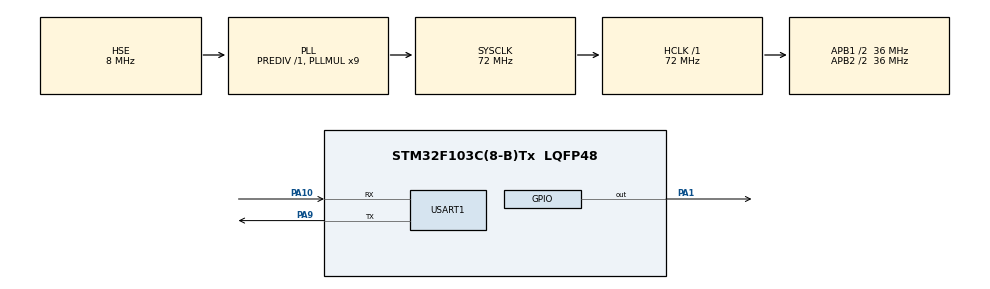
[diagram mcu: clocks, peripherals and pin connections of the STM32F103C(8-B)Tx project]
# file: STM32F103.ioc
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Mcu.Family=STM32F1
Mcu.Name=STM32F103C(8-B)Tx
Mcu.Package=LQFP48
NVIC.PriorityGroup=NVIC_PRIORITYGROUP_4
NVIC.USART1_IRQn=true\:0\:0\:false\:false\:true\:true\:true\:true
PA0-WKUP.Mode=SYS_WakeUp0
PA0-WKUP.Signal=SYS_WKUP
PA1.Signal=GPIO_Output
PA10.Mode=Asynchronous
PA10.Signal=USART1_RX
PA13.Mode=Serial_Wire
PA13.Signal=SYS_JTMS-SWDIO
PA14.Mode=Serial_Wire
PA14.Signal=SYS_JTCK-SWCLK
PA9.Mode=Asynchronous
PA9.Signal=USART1_TX
PD0-OSC_IN.Mode=HSE-External-Oscillator
PD0-OSC_IN.Signal=RCC_OSC_IN
PD1-OSC_OUT.Mode=HSE-External-Oscillator
PD1-OSC_OUT.Signal=RCC_OSC_OUT
ProjectManager.HeapSize=0x200
ProjectManager.StackSize=0x400
ProjectManager.TargetToolchain=MDK-ARM V5.32
RCC.AHBFreq_Value=72000000
RCC.APB1CLKDivider=RCC_HCLK_DIV2
RCC.APB1Freq_Value=36000000
RCC.APB1TimFreq_Value=72000000
RCC.APB2CLKDivider=RCC_HCLK_DIV2
RCC.APB2Freq_Value=36000000
RCC.APB2TimFreq_Value=72000000
RCC.HCLKFreq_Value=72000000
RCC.PLLMUL=RCC_PLL_MUL9
RCC.PLLSourceVirtual=RCC_PLLSOURCE_HSE
RCC.SYSCLKFreq_VALUE=72000000
RCC.SYSCLKSource=RCC_SYSCLKSOURCE_PLLCLK
RCC.USBFreq_Value=72000000
TIM2.Prescaler=71
USART1.VirtualMode=VM_ASYNC
VP_TIM2_VS_ClockSourceINT.Mode=Internal
board=custom

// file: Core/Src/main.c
/* USER CODE BEGIN Header */
/**
  ******************************************************************************
  * @file           : main.c
  * @brief          : Main program body
  ******************************************************************************
  * @attention
  *
  * Copyright (c) 2026 STMicroelectronics.
  * All rights reserved.
  *
  * This software is licensed under terms that can be found in the LICENSE file
  * in the root directory of this software component.
  * If no LICENSE file comes with this software, it is provided AS-IS.
  *
  ******************************************************************************
  */
/* USER CODE END Header */
#include "main.h"
#include "tim.h"
#include "usart.h"
#include "gpio.h"

/* USER CODE BEGIN Includes */
#include <stdio.h>
#include "delay.h"
#include "dht11.h"
#include <string.h>
/* USER CODE END Includes */

/* USER CODE BEGIN PV */
extern UART_HandleTypeDef huart1;
/* USER CODE END PV */

void SystemClock_Config(void);

/* USER CODE BEGIN 0 */
int fputc(int ch, FILE *f)
{
  HAL_UART_Transmit(&huart1, (uint8_t *)&ch, 1, 0xFFFF);
  return ch;
}
uint16_t MakeProtocolFrame(char *buf, float temp, float humi)
{
  // 自动拼接：#（帧头） + 数据 + \r\n（帧尾）
  uint16_t len = sprintf(buf, "#T=%.1f,H=%.1f\r\n", temp, humi);
  return len;
}
/* USER CODE END 0 */

int main(void)
{

  /* MCU Configuration--------------------------------------------------------*/

  /* Reset of all peripherals, Initializes the Flash interface and the Systick. */
  HAL_Init();

  /* USER CODE BEGIN Init */

  SystemClock_Config();       // 配置系统时钟为72MHz（CubeMX生成的函数）
  MX_GPIO_Init();             // 初始化其他GPIO（如果有）

  /* USER CODE END Init */

  /* Configure the system clock */
  SystemClock_Config();

  /* Initialize all configured peripherals */
  MX_GPIO_Init();
  MX_TIM2_Init();
  HAL_TIM_Base_Start(&htim2); // 启动 TIM2 计数
  MX_USART1_UART_Init();
  /* USER CODE BEGIN 2 */
  DHT11_Init();
  // 定义一个变量存储结果，调用 DHT11_Read
  float temperature = 0.0f;
  float humidity = 0.0f;

  /* USER CODE END 2 */

  /* Infinite loop */
  while (1)
  {
    uint8_t status;
    // 关闭全局中断，防止串口中断打断DHT时序
    __disable_irq();
    status = DHT11_Read(&temperature, &humidity);
    __enable_irq(); // 读完恢复中断

    //printf("status=%d\r\n", status);
    if (status == 0)
    {
      char send_buf[64];
      // 1.组包，自动带上【帧头#】和【帧尾\r\n】
      uint16_t frame_len = MakeProtocolFrame(send_buf, temperature, humidity);

      // 2.发送完整协议帧
      HAL_UART_Transmit(
          &huart1,
          (uint8_t *)send_buf,
          frame_len,
          100);
    }
    else
    {
      printf("DHT11 read error\r\n");
    }
    HAL_Delay(2000);

  }
}

void SystemClock_Config(void)
{
  RCC_OscInitTypeDef RCC_OscInitStruct = {0};
  RCC_ClkInitTypeDef RCC_ClkInitStruct = {0};

  /** Initializes the RCC Oscillators according to the specified parameters
  * in the RCC_OscInitTypeDef structure.
  */
  RCC_OscInitStruct.OscillatorType = RCC_OSCILLATORTYPE_HSE;
  RCC_OscInitStruct.HSEState = RCC_HSE_ON;
  RCC_OscInitStruct.HSEPredivValue = RCC_HSE_PREDIV_DIV1;
  RCC_OscInitStruct.HSIState = RCC_HSI_ON;
  RCC_OscInitStruct.PLL.PLLState = RCC_PLL_ON;
  RCC_OscInitStruct.PLL.PLLSource = RCC_PLLSOURCE_HSE;
  RCC_OscInitStruct.PLL.PLLMUL = RCC_PLL_MUL9;
  if (HAL_RCC_OscConfig(&RCC_OscInitStruct) != HAL_OK)
  {
    Error_Handler();
  }

  /** Initializes the CPU, AHB and APB buses clocks
  */
  RCC_ClkInitStruct.ClockType = RCC_CLOCKTYPE_HCLK|RCC_CLOCKTYPE_SYSCLK
                              |RCC_CLOCKTYPE_PCLK1|RCC_CLOCKTYPE_PCLK2;
  RCC_ClkInitStruct.SYSCLKSource = RCC_SYSCLKSOURCE_PLLCLK;
  RCC_ClkInitStruct.AHBCLKDivider = RCC_SYSCLK_DIV1;
  RCC_ClkInitStruct.APB1CLKDivider = RCC_HCLK_DIV2;
  RCC_ClkInitStruct.APB2CLKDivider = RCC_HCLK_DIV2;

  if (HAL_RCC_ClockConfig(&RCC_ClkInitStruct, FLASH_LATENCY_2) != HAL_OK)
  {
    Error_Handler();
  }
}

void Error_Handler(void)
{
  __disable_irq();
  while (1)
  {
  }
}
